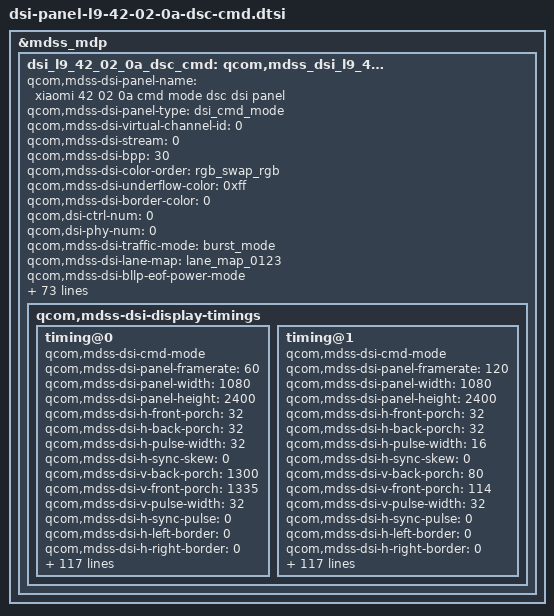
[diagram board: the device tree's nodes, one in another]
&mdss_mdp {
	dsi_l9_42_02_0a_dsc_cmd: qcom,mdss_dsi_l9_42_02_0a_dsc_cmd {
		qcom,mdss-dsi-panel-name = "xiaomi 42 02 0a cmd mode dsc dsi panel";
		qcom,mdss-dsi-panel-type = "dsi_cmd_mode";
		qcom,mdss-dsi-virtual-channel-id = <0>;
		qcom,mdss-dsi-stream = <0>;
		qcom,mdss-dsi-bpp = <30>;
		qcom,mdss-dsi-color-order = "rgb_swap_rgb";
		qcom,mdss-dsi-underflow-color = <0xff>;
		qcom,mdss-dsi-border-color = <0>;

		qcom,dsi-ctrl-num = <0>;
		qcom,dsi-phy-num = <0>;

		qcom,mdss-dsi-traffic-mode = "burst_mode";
		qcom,mdss-dsi-lane-map = "lane_map_0123";
		qcom,mdss-dsi-bllp-eof-power-mode;
		qcom,mdss-dsi-bllp-power-mode;
		qcom,mdss-dsi-lane-0-state;
		qcom,mdss-dsi-lane-1-state;
		qcom,mdss-dsi-lane-2-state;
		qcom,mdss-dsi-lane-3-state;
		qcom,mdss-dsi-dma-trigger = "trigger_sw";
		qcom,mdss-dsi-mdp-trigger = "none";
		qcom,mdss-dsi-reset-sequence =  <1 11>, <0 1>, <1 11>;
		qcom,mdss-pan-physical-width-dimension = <683>;
		qcom,mdss-pan-physical-height-dimension = <1517>;
		qcom,mdss-dsi-te-pin-select = <1>;
		qcom,mdss-dsi-wr-mem-start = <0x2c>;
		qcom,mdss-dsi-wr-mem-continue = <0x3c>;
		qcom,mdss-dsi-te-dcs-command = <1>;
		qcom,mdss-dsi-te-check-enable;
		qcom,mdss-dsi-te-using-te-pin;
		qcom,mdss-dsi-tx-eot-append;
		qcom,mdss-dsi-lp11-init;

		qcom,mdss-dsi-bl-inverted-dbv;
		qcom,bl-update-flag = "delay_until_first_frame";
		qcom,mdss-dsi-panel-mode-switch;

		qcom,mdss-dsi-panel-hdr-enabled;
		qcom,mdss-dsi-panel-hdr-color-primaries = <14500 15500 32000 17000 15500 30000 8000 3000>;
		qcom,mdss-dsi-panel-peak-brightness = <4200000>;
		qcom,mdss-dsi-panel-blackness-level = <3230>;

		qcom,mdss-dsi-display-timings {
			timing@0{
				qcom,mdss-dsi-cmd-mode;
				qcom,mdss-dsi-panel-framerate = <60>;
				qcom,mdss-dsi-panel-width = <1080>;
				qcom,mdss-dsi-panel-height = <2400>;
				qcom,mdss-dsi-h-front-porch = <32>;
				qcom,mdss-dsi-h-back-porch = <32>;
				qcom,mdss-dsi-h-pulse-width = <32>;
				qcom,mdss-dsi-h-sync-skew = <0>;
				qcom,mdss-dsi-v-back-porch = <1300>;
				qcom,mdss-dsi-v-front-porch = <1335>;
				qcom,mdss-dsi-v-pulse-width = <32>;
				qcom,mdss-dsi-h-sync-pulse = <0>;
				qcom,mdss-dsi-h-left-border = <0>;
				qcom,mdss-dsi-h-right-border = <0>;
				qcom,mdss-dsi-v-top-border = <0>;
				qcom,mdss-dsi-v-bottom-border = <0>;
				qcom,mdss-dsi-panel-clockrate = <831000000>;
				qcom,mdss-dsi-panel-jitter = <0x5 0x1>;
				qcom,mdss-mdp-transfer-time-us = <7000>;
				qcom,mdss-dsi-on-command = [
					/* VDC setting */
					39 01 00 00 00 00 06 F0 55 AA 52 08 08
					39 00 00 00 00 00 05 E9 00 00 00 16
					39 00 00 00 00 00 02 6F 07
					39 00 00 00 00 00 05 B9 05 DB 00 7A
					/* RCN setting */
					39 00 00 00 00 00 05 FF AA 55 A5 80
					39 00 00 00 00 00 02 6F 1D
					39 00 00 00 00 00 02 F2 05
					/* Page 0 */
					39 00 00 00 00 00 06 F0 55 AA 52 08 00
					39 00 00 00 00 00 02 6F 01
					39 00 00 00 00 00 02 CA AA
					/* flash reload */
					39 00 00 00 00 00 02 6F 01
					39 00 00 00 00 00 02 C0 B3
					39 00 00 00 00 00 02 6F 11
					39 00 00 00 00 00 02 C0 30
					39 00 00 00 00 00 02 6F 1C
					/* Demura gain */
					39 00 00 00 00 00 03 C0 03 12
					/* VBP & VFP */
					39 00 00 00 00 00 05 3B 00 14 00 12
					/* DSC Setting */
					39 00 00 00 00 00 02 90 01
					39 00 00 00 00 00 13 91 AB 28 00 0C C2 00 03 1C 01 7E 00 0F 08 BB 04 3D 10 F0
					39 00 00 00 00 00 02 03 01
					39 00 00 00 00 00 02 2C 00
					/* Round Off */
					39 00 00 00 00 00 06 F0 55 AA 52 08 07
					39 00 00 00 00 00 02 C0 01
					39 00 00 00 00 00 02 C1 00
					39 00 00 00 00 00 02 C2 00
					39 00 00 00 00 00 02 C3 00
					39 00 00 00 00 00 02 C4 00
					39 00 00 00 00 00 02 C5 00
					39 00 00 00 00 00 02 C6 00
					39 00 00 00 00 00 02 C7 00
					39 00 00 00 00 00 02 C8 00
					39 00 00 00 00 00 02 CD 00
					39 00 00 00 00 00 02 CE 00
					39 00 00 00 00 00 02 CF 00
					39 00 00 00 00 00 02 D0 00
					/* Dimming OFF Setting */
					39 00 00 00 00 00 02 53 20
					/* page 0 */
					39 00 00 00 00 00 06 F0 55 AA 52 08 00
					/* Dimming 8 frame */
					39 00 00 00 00 00 02 6F 02
					39 00 00 00 00 00 03 B2 08 08
					/* TE ON Setting */
					39 00 00 00 00 00 02 35 00
					/* CASET/RASET Setting */
					39 00 00 00 00 00 05 2A 00 00 04 37 /* CASET 1080 */
					39 00 00 00 00 00 05 2B 00 00 09 5F /* PASET 2400 */
					/* MIPI Speed = 831Mbps @osc 128Mhz */
					/* page 1 */
					39 00 00 00 00 00 06 F0 55 AA 52 08 01
					39 00 00 00 00 00 08 C3 94 01 8C D0 22 02 00
					/* Frame Rate 60Hz */
					39 00 00 00 00 00 02 2F 02
					/* GIR OFF */
					39 00 00 00 00 00 02 5F 01
					/* Page 0 */
					39 00 00 00 00 00 06 F0 55 AA 52 08 00
					39 00 00 00 00 00 02 6F 09
					/* Normal gamma */
					39 00 00 00 00 00 02 C0 00
					/* Page 2 */
					39 00 00 00 00 00 06 F0 55 AA 52 08 02
					39 00 00 00 00 00 02 CC 30
					39 01 00 00 14 00 02 CE 01
					39 00 00 00 00 00 02 CC 00
					/* cmd3: aod no black */
					39 00 00 00 00 00 05 FF AA 55 A5 80
					39 00 00 00 00 00 02 6F 61
					39 00 00 00 00 00 02 F3 80
					39 00 00 00 00 00 06 F0 55 AA 52 08 01
					39 00 00 00 00 00 02 6F 01
					39 00 00 00 00 00 04 D2 00 00 11
					39 00 00 00 00 00 02 6F 06
					39 00 00 00 00 00 02 D2 05
					39 00 00 00 00 00 02 6F 0F
					39 00 00 00 00 00 02 D2 00
					39 00 00 00 00 00 02 6F 09
					39 00 00 00 00 00 03 D2 00 00
					/* Close ELVSS and ELVDD PMIC-Fast Discharge*/
					39 00 00 00 00 00 06 F0 55 AA 52 08 01
					39 01 00 00 00 00 02 CE 08
					/* Sleep Out */
					39 01 00 00 78 00 02 11 00
					/* Display On */
					39 01 00 00 00 00 02 29 00
					/* Close ELVSS and ELVDD PMIC-Fast Discharge*/
					39 00 00 00 00 00 06 F0 55 AA 52 08 01
					39 01 00 00 00 00 02 CE 00];
				qcom,mdss-dsi-off-command = [
					39 01 00 00 0A 00 02 28 00
					39 01 00 00 78 00 02 10 00];
				qcom,mdss-dsi-on-command-state = "dsi_lp_mode";
				qcom,mdss-dsi-off-command-state = "dsi_lp_mode";

				qcom,mdss-dsi-timing-switch-command = [
					/* Frame Rate 60Hz GIR off*/
					/* page 0 */
					39 01 00 00 00 00 06 F0 55 AA 52 08 00
					/* 60Hz */
					39 00 00 00 00 00 02 2F 02
					/* GIR OFF */
					39 00 00 00 00 00 02 5F 01
					39 00 00 00 00 00 06 F0 55 AA 52 08 00
					39 00 00 00 00 00 02 6F 09
					/* Normal gamma */
					39 00 00 00 00 00 02 C0 00
					/* Page 2 */
					39 00 00 00 00 00 06 F0 55 AA 52 08 02
					39 00 00 00 00 00 02 CC 30
					39 01 00 00 14 00 02 CE 01
					39 01 00 00 00 00 02 CC 00
				];
				qcom,mdss-dsi-timing-switch-command-state = "dsi_hs_mode";

				qcom,mdss-dsi-lp1-command = [
					39 01 00 00 14 00 02 39 00
					39 01 00 00 00 00 02 2C 00];
				qcom,mdss-dsi-lp1-commandd-state = "dsi_hs_mode";

				qcom,mdss-dsi-nolp-command = [
					39 01 00 00 32 00 02 38 00
					39 01 00 00 00 00 02 2C 00];
				qcom,mdss-dsi-nolp-command-state = "dsi_hs_mode";

				qcom,compression-mode = "dsc";
				qcom,mdss-dsc-version = <0x11>;
				qcom,mdss-dsc-scr-version = <0x0>;
				qcom,mdss-dsc-slice-height = <12>;
				qcom,mdss-dsc-slice-width = <1080>;
				qcom,mdss-dsc-slice-per-pkt = <1>;
				qcom,mdss-dsc-bit-per-component = <10>;
				qcom,mdss-dsc-bit-per-pixel = <8>;
				qcom,mdss-dsc-block-prediction-enable;
			};
			timing@1{
				qcom,mdss-dsi-cmd-mode;
				qcom,mdss-dsi-panel-framerate = <120>;
				qcom,mdss-dsi-panel-width = <1080>;
				qcom,mdss-dsi-panel-height = <2400>;
				qcom,mdss-dsi-h-front-porch = <32>;
				qcom,mdss-dsi-h-back-porch = <32>;
				qcom,mdss-dsi-h-pulse-width = <16>;
				qcom,mdss-dsi-h-sync-skew = <0>;
				qcom,mdss-dsi-v-back-porch = <80>;
				qcom,mdss-dsi-v-front-porch = <114>;
				qcom,mdss-dsi-v-pulse-width = <32>;
				qcom,mdss-dsi-h-sync-pulse = <0>;
				qcom,mdss-dsi-h-left-border = <0>;
				qcom,mdss-dsi-h-right-border = <0>;
				qcom,mdss-dsi-v-top-border = <0>;
				qcom,mdss-dsi-v-bottom-border = <0>;
				qcom,mdss-dsi-panel-clockrate = <831000000>;
				qcom,mdss-dsi-panel-jitter = <0x5 0x1>;
				qcom,mdss-mdp-transfer-time-us = <7000>;
				qcom,mdss-dsi-on-command = [
					/* VDC setting */
					39 01 00 00 00 00 06 F0 55 AA 52 08 08
					39 00 00 00 00 00 05 E9 00 00 00 16
					39 00 00 00 00 00 02 6F 07
					39 00 00 00 00 00 05 B9 05 DB 00 7A
					/* RCN setting */
					39 00 00 00 00 00 05 FF AA 55 A5 80
					39 00 00 00 00 00 02 6F 1D
					39 00 00 00 00 00 02 F2 05
					/* Page 0 */
					39 00 00 00 00 00 06 F0 55 AA 52 08 00
					39 00 00 00 00 00 02 6F 01
					39 00 00 00 00 00 02 CA AA
					/* flash reload */
					39 00 00 00 00 00 02 6F 01
					39 00 00 00 00 00 02 C0 B3
					39 00 00 00 00 00 02 6F 11
					39 00 00 00 00 00 02 C0 30
					39 00 00 00 00 00 02 6F 1C
					/* Demura gain */
					39 00 00 00 00 00 03 C0 03 12
					/* VBP & VFP */
					39 00 00 00 00 00 05 3B 00 14 00 12
					/* DSC Setting */
					39 00 00 00 00 00 02 90 01
					39 00 00 00 00 00 13 91 AB 28 00 0C C2 00 03 1C 01 7E 00 0F 08 BB 04 3D 10 F0
					39 00 00 00 00 00 02 03 01
					39 00 00 00 00 00 02 2C 00
					/* Round Off */
					39 00 00 00 00 00 06 F0 55 AA 52 08 07
					39 00 00 00 00 00 02 C0 01
					39 00 00 00 00 00 02 C1 00
					39 00 00 00 00 00 02 C2 00
					39 00 00 00 00 00 02 C3 00
					39 00 00 00 00 00 02 C4 00
					39 00 00 00 00 00 02 C5 00
					39 00 00 00 00 00 02 C6 00
					39 00 00 00 00 00 02 C7 00
					39 00 00 00 00 00 02 C8 00
					39 00 00 00 00 00 02 CD 00
					39 00 00 00 00 00 02 CE 00
					39 00 00 00 00 00 02 CF 00
					39 00 00 00 00 00 02 D0 00
					/* Dimming OFF Setting */
					39 00 00 00 00 00 02 53 20
					/* page 0 */
					39 00 00 00 00 00 06 F0 55 AA 52 08 00
					/* Dimming 8 frame */
					39 00 00 00 00 00 02 6F 02
					39 00 00 00 00 00 03 B2 08 08
					/* TE ON Setting */
					39 00 00 00 00 00 02 35 00
					/* CASET/RASET Setting */
					39 00 00 00 00 00 05 2A 00 00 04 37 /* CASET 1080 */
					39 00 00 00 00 00 05 2B 00 00 09 5F /* PASET 2400 */
					/* MIPI Speed = 831Mbps @osc 128Mhz */
					/* page 1 */
					39 00 00 00 00 00 06 F0 55 AA 52 08 01
					39 00 00 00 00 00 08 C3 94 01 8C D0 22 02 00
					/* Frame Rate 120Hz */
					39 00 00 00 00 00 02 2F 03
					/* GIR OFF */
					39 00 00 00 00 00 02 5F 01
					/* Page 0 */
					39 00 00 00 00 00 06 F0 55 AA 52 08 00
					39 00 00 00 00 00 02 6F 0A
					/* Preset1 gamma */
					39 00 00 00 00 00 02 C0 20
					/* Page 2 */
					39 00 00 00 00 00 06 F0 55
					 AA 52 08 02
					39 00 00 00 00 00 02 CC 30
					39 01 00 00 14 00 02 CE 01
					39 00 00 00 00 00 02 CC 00
					/* cmd3: aod no black */
					39 00 00 00 00 00 05 FF AA 55 A5 80
					39 00 00 00 00 00 02 6F 61
					39 00 00 00 00 00 02 F3 80
					39 00 00 00 00 00 06 F0 55 AA 52 08 01
					39 00 00 00 00 00 02 6F 01
					39 00 00 00 00 00 04 D2 00 00 11
					39 00 00 00 00 00 02 6F 06
					39 00 00 00 00 00 02 D2 05
					39 00 00 00 00 00 02 6F 0F
					39 00 00 00 00 00 02 D2 00
					39 00 00 00 00 00 02 6F 09
					39 00 00 00 00 00 03 D2 00 00
					/* Close ELVSS and ELVDD PMIC-Fast Discharge*/
					39 00 00 00 00 00 06 F0 55 AA 52 08 01
					39 01 00 00 00 00 02 CE 08
					/* Sleep Out */
					39 01 00 00 78 00 02 11 00
					/* Display On */
					39 01 00 00 00 00 02 29 00
					/* Close ELVSS and ELVDD PMIC-Fast Discharge*/
					39 00 00 00 00 00 06 F0 55 AA 52 08 01
					39 01 00 00 00 00 02 CE 00];
				qcom,mdss-dsi-off-command = [
					39 01 00 00 14 00 02 28 00
					39 01 00 00 78 00 02 10 00];
				qcom,mdss-dsi-on-command-state = "dsi_lp_mode";
				qcom,mdss-dsi-off-command-state = "dsi_lp_mode";

				qcom,mdss-dsi-timing-switch-command = [
					/* Frame Rate 120Hz GIR off*/
					/* Page 0 */
					39 01 00 00 00 00 06 F0 55 AA 52 08 00
					/* 120Hz */
					39 00 00 00 00 00 02 2F 03
					/* GIR OFF */
					39 00 00 00 00 00 02 5F 01
					39 00 00 00 00 00 06 F0 55 AA 52 08 00
					39 00 00 00 00 00 02 6F 0A
					/* Preset1 gamma */
					39 00 00 00 00 00 02 C0 20
					/* Page 2 */
					39 00 00 00 00 00 06 F0 55 AA 52 08 02
					39 00 00 00 00 00 02 CC 30
					39 01 00 00 14 00 02 CE 01
					39 01 00 00 00 00 02 CC 00

				];
				qcom,mdss-dsi-timing-switch-command-state = "dsi_hs_mode";

				qcom,mdss-dsi-lp1-command = [
					39 01 00 00 14 00 02 39 00
					39 01 00 00 00 00 02 2C 00];
				qcom,mdss-dsi-lp1-commandd-state = "dsi_hs_mode";

				qcom,mdss-dsi-nolp-command = [
					39 01 00 00 32 00 02 38 00
					39 01 00 00 00 00 02 2C 00];
				qcom,mdss-dsi-nolp-command-state = "dsi_hs_mode";

				qcom,compression-mode = "dsc";
				qcom,mdss-dsc-version = <0x11>;
				qcom,mdss-dsc-scr-version = <0x0>;
				qcom,mdss-dsc-slice-height = <12>;
				qcom,mdss-dsc-slice-width = <1080>;
				qcom,mdss-dsc-slice-per-pkt = <1>;
				qcom,mdss-dsc-bit-per-component = <10>;
				qcom,mdss-dsc-bit-per-pixel = <8>;
				qcom,mdss-dsc-block-prediction-enable;
			};
		};
	};
};

&dsi_l9_42_02_0a_dsc_cmd {
	mi,panel-id = <0x00004C39 0x00420200>;
	mi,hbm-51-ctl-flag;
	mi,bl-51ctl-32bit-flag;
	mi,aod-bl-51ctl-flag;
	mi,aod-brightness = <0x155 0x0FFE>;
	mi,hbm-off-51-index = <0>;
	mi,hbm-fod-off-51-index = <0>;
	mi,hbm-bl-min-level = <1>;
	mi,hbm-bl-max-level = <2047>;
	mi,max-brightness-clone = <4095>;
	mi,thermal-dimming-flag;
	mi,mdss-dsi-panel-dc-type = <0>;

	mi,panel-hbm-backlight-threshold = <2047>;

	mi,local-hbm-enabled;
	mi,local-hbm-off-to-hbm-51-index = <1>;
	mi,local-hbm-off-to-normal-51-index = <1>;
	mi,local-hbm-normal-alpha-87-index = <13>;
	mi,local-hbm-hlpm-alpha-87-index = <16>;
	mi,local-hbm-on-87-index = <11>;
	mi,local-hbm-hlpm-on-87-index = <14>;
	mi,doze-hbm-dbv-level = <245>;
	mi,doze-lbm-dbv-level = <20>;
	mi,fod-low-brightness-clone-threshold = <38>;
	mi,fod-low-brightness-lux-threshold = <1>;

	mi,flatmode-update-flag;
	mi,flatmode-on-b9-index = <3>;
	mi,update-vdc-param-enabled;
	mi,dsi-on-e9-index = <1>;
	mi,dsi-on-b9-index = <3>;

	mi,lhbm-update-flag;

	/* IRQF_ONESHOT | IRQF_TRIGGER_FALLING */
	mi,esd-err-irq-gpio = <&tlmm 3 0x2002>;

	mi,panel-aod-to-off-command-need-enabled;

	mi,panel-on-dimming-delay = <120>;

	qcom,esd-check-enabled;
	qcom,esd-aod-check-enabled;
	qcom,mdss-dsi-panel-status-check-mode = "reg_read";
	qcom,mdss-dsi-panel-status-offset-command = [
		39 01 00 00 00 00 05 FF AA 55 A5 81
		15 01 00 00 00 00 02 6F 0F];
	qcom,mdss-dsi-panel-status-command = [06 01 00 00 00 00 01 FA];
	qcom,mdss-dsi-panel-status-command-state = "dsi_lp_mode";
	qcom,mdss-dsi-panel-status-offset-command-state = "dsi_lp_mode";
	qcom,mdss-dsi-panel-status-value = <0x00>;
	qcom,mdss-dsi-panel-status-read-length = <1>;

	qcom,mdss-dsi-display-timings {
		timing@0{ /* 60hz */
			mi,mdss-dsc-panel-id = <0x00004C39 0x00420200>;
			mi,mdss-dsi-dimmingon-command = [15 01 00 00 00 00 02 53 28];
			mi,mdss-dsi-dimmingon-command-state = "dsi_hs_mode";
			mi,mdss-dsi-dimmingoff-command = [15 01 00 00 00 00 02 53 20];
			mi,mdss-dsi-dimmingoff-command-state = "dsi_hs_mode";

			mi,mdss-dsi-hbm-on-command = [39 01 00 00 00 00 03 51 0F FF];
			mi,mdss-dsi-hbm-on-command-state = "dsi_hs_mode";
			mi,mdss-dsi-hbm-off-command = [39 01 00 00 00 00 03 51 07 FF];
			mi,mdss-dsi-hbm-off-command-state = "dsi_hs_mode";

			mi,mdss-dsi-doze-hbm-command = [
				39 01 00 00 00 00 05 51 00 F5 0F FE
				39 01 00 00 14 00 02 39 00
				39 01 00 00 00 00 02 2C 00
			];
			mi,mdss-dsi-doze-hbm-command-state = "dsi_hs_mode";
			mi,mdss-dsi-doze-lbm-command = [
				39 01 00 00 00 00 05 51 00 14 01 55
				39 01 00 00 32 00 02 39 00
				39 01 00 00 00 00 02 2C 00
			];
			mi,mdss-dsi-doze-lbm-command-state = "dsi_hs_mode";

			mi,mdss-dsi-doze-hbm-nolp-command = [
				/* AOD off */
				39 01 00 00 32 00 02 38 00
				39 00 00 00 00 00 02 2C 00
				39 01 00 00 00 00 05 51 00 F5 0F FE
			];
			mi,mdss-dsi-doze-hbm-nolp-command-state = "dsi_hs_mode";
			mi,mdss-dsi-doze-lbm-nolp-command = [
				/* AOD off */
				39 01 00 00 32 00 02 38 00
				39 00 00 00 00 00 02 2C 00
				39 01 00 00 00 00 05 51 00 14 01 55
			];
			mi,mdss-dsi-doze-lbm-nolp-command-state = "dsi_hs_mode";

			mi,mdss-dsi-doze-none-nolp-command = [
				/* AOD off */
				39 01 00 00 32 00 02 38 00
				39 01 00 00 00 00 02 2C 00
			];
			mi,mdss-dsi-doze-none-nolp-command-state = "dsi_hs_mode";

			mi,mdss-dsi-local-hbm-normal-white-1000nit-command = [
				39 01 00 00 00 00 06 F0 55 AA 52 08 00
				39 00 00 00 00 00 02 6F 17
				39 00 00 00 00 00 03 B2 07 FF
				39 00 00 00 00 00 02 6F 1F
				39 00 00 00 00 00 03 B2 00 50
				39 00 00 00 00 00 06 F0 55 AA 52 08 02
				39 00 00 00 00 00 02 D1 01
				39 00 00 00 00 00 02 6F 08
				39 00 00 00 00 00 07 D0 0B 07 09 7B 0C 1D
				39 00 00 00 00 00 06 F0 55 AA 52 08 07
				39 00 00 00 00 00 02 D9 40
				39 00 00 00 00 00 02 6F 01
				39 00 00 00 00 00 05 88 02 1C 08 65
				39 00 00 00 00 00 03 87 1F FF
				39 00 00 00 00 00 03 51 07 FF
				39 00 00 00 00 00 02 88 01
				39 01 00 00 42 00 02 85 01
			];
			mi,mdss-dsi-local-hbm-normal-white-1000nit-command-state = "dsi_hs_mode";

			mi,mdss-dsi-local-hbm-hlpm-white-1000nit-command = [
				/* AOD off */
				39 01 00 00 32 00 02 38 00
				39 00 00 00 00 00 02 2C 00
				/* 60HZ */
				39 00 00 00 00 00 02 2F 02
				/* Local HBM setting*/
				39 00 00 00 00 00 06 F0 55 AA 52 08 00
				39 00 00 00 00 00 02 6F 17
				39 00 00 00 00 00 03 B2 07 FF
				39 00 00 00 00 00 02 6F 1F
				39 00 00 00 00 00 03 B2 00 50
				39 00 00 00 00 00 06 F0 55 AA 52 08 02
				39 00 00 00 00 00 02 D1 01
				39 00 00 00 00 00 02 6F 08
				39 00 00 00 00 00 07 D0 0B 07 09 7B 0C 1D
				39 00 00 00 00 00 06 F0 55 AA 52 08 07
				39 00 00 00 00 00 02 D9 40
				39 00 00 00 00 00 02 6F 01
				39 00 00 00 00 00 05 88 02 1C 08 65
				39 00 00 00 00 00 03 87 1F FF
				39 00 00 00 00 00 03 51 07 FF
				39 00 00 00 00 00 02 88 01
				39 01 00 00 42 00 02 85 01
			];
			mi,mdss-dsi-local-hbm-hlpm-white-1000nit-command-state = "dsi_hs_mode";

			mi,mdss-dsi-local-hbm-normal-white-110nit-command = [
				39 01 00 00 00 00 06 F0 55 AA 52 08 00
				39 00 00 00 00 00 02 6F 17
				39 00 00 00 00 00 03 B2 07 FF
				39 00 00 00 00 00 02 6F 1F
				39 00 00 00 00 00 03 B2 00 50
				39 00 00 00 00 00 06 F0 55 AA 52 08 02
				39 00 00 00 00 00 02 D1 01
				39 00 00 00 00 00 02 6F 08
				39 00 00 00 00 00 07 D0 07 62 06 74 07 F7
				39 00 00 00 00 00 06 F0 55 AA 52 08 07
				39 00 00 00 00 00 02 D9 40
				39 00 00 00 00 00 02 6F 01
				39 00 00 00 00 00 05 88 02 1C 08 65
				39 00 00 00 00 00 03 87 1F FF
				39 00 00 00 00 00 03 51 07 FF
				39 00 00 00 00 00 02 88 01
				39 01 00 00 42 00 02 85 01
			];
			mi,mdss-dsi-local-hbm-normal-white-110nit-command-state = "dsi_hs_mode";

			mi,mdss-dsi-local-hbm-hlpm-white-110nit-command = [
				/* AOD off */
				39 01 00 00 32 00 02 38 00
				39 00 00 00 00 00 02 2C 00
				/* 60HZ */
				39 00 00 00 00 00 02 2F 02
				/* Local HBM setting*/
				39 00 00 00 00 00 06 F0 55 AA 52 08 00
				39 00 00 00 00 00 02 6F 17
				39 00 00 00 00 00 03 B2 07 FF
				39 00 00 00 00 00 02 6F 1F
				39 00 00 00 00 00 03 B2 00 50
				39 00 00 00 00 00 06 F0 55 AA 52 08 02
				39 00 00 00 00 00 02 D1 01
				39 00 00 00 00 00 02 6F 08
				39 00 00 00 00 00 07 D0 07 62 06 74 07 F7
				39 00 00 00 00 00 06 F0 55 AA 52 08 07
				39 00 00 00 00 00 02 D9 40
				39 00 00 00 00 00 02 6F 01
				39 00 00 00 00 00 05 88 02 1C 08 65
				39 00 00 00 00 00 03 87 1F FF
				39 00 00 00 00 00 03 51 07 FF
				39 00 00 00 00 00 02 88 01
				39 01 00 00 42 00 02 85 01
			];
			mi,mdss-dsi-local-hbm-hlpm-white-110nit-command-state = "dsi_hs_mode";

			mi,mdss-dsi-local-hbm-normal-green-500nit-command = [
				39 01 00 00 00 00 06 F0 55 AA 52 08 00
				39 00 00 00 00 00 02 6F 17
				39 00 00 00 00 00 03 B2 07 FF
				39 00 00 00 00 00 02 6F 1F
				39 00 00 00 00 00 03 B2 00 50
				39 00 00 00 00 00 06 F0 55 AA 52 08 02
				39 00 00 00 00 00 02 D1 01
				39 00 00 00 00 00 02 6F 08
				39 00 00 00 00 00 07 D0 00 00 09 40 00 00
				39 00 00 00 00 00 06 F0 55 AA 52 08 07
				39 00 00 00 00 00 02 D9 40
				39 00 00 00 00 00 02 6F 01
				39 00 00 00 00 00 05 88 02 1C 08 65
				39 00 00 00 00 00 03 87 1F FF
				39 00 00 00 00 00 03 51 07 FF
				39 00 00 00 00 00 02 88 01
				39 01 00 00 42 00 02 85 01
			];
			mi,mdss-dsi-local-hbm-normal-green-500nit-command-state = "dsi_hs_mode";

			mi,mdss-dsi-local-hbm-off-to-normal-command = [
				39 01 00 00 00 00 02 53 20
				39 00 00 00 00 00 03 51 00 00
				39 00 00 00 00 00 03 87 0F FF
				39 00 00 00 00 00 02 88 01
				39 01 00 00 0A 00 02 86 01
			];
			mi,mdss-dsi-local-hbm-off-to-normal-command-state = "dsi_hs_mode";

			mi,mdss-dsi-local-hbm-off-to-hbm-command = [
				39 01 00 00 00 00 02 53 20
				39 00 00 00 00 00 03 51 00 00
				39 00 00 00 00 00 03 87 0F FF
				39 00 00 00 00 00 02 88 01
				39 01 00 00 0A 00 02 86 01
			];
			mi,mdss-dsi-local-hbm-off-to-hbm-command-state = "dsi_hs_mode";

			mi,mdss-dsi-local-hbm-off-to-hlpm-command = [
				/* local hbm off */
				39 01 00 00 00 00 02 53 20
				39 00 00 00 00 00 03 51 00 00
				39 00 00 00 00 00 03 87 0F FF
				39 00 00 00 00 00 02 88 01
				39 01 00 00 0A 00 02 86 01
				/* aod hbm */
				39 01 00 00 14 00 02 39 00
				39 01 00 00 00 00 02 2C 00
			];
			mi,mdss-dsi-local-hbm-off-to-hlpm-command-state = "dsi_hs_mode";

			mi,mdss-dsi-local-hbm-off-to-llpm-command = [
				/* local hbm off */
				39 01 00 00 00 00 02 53 20
				39 00 00 00 00 00 03 51 00 00
				39 00 00 00 00 00 03 87 0F FF
				39 00 00 00 00 00 02 88 01
				39 01 00 00 0A 00 02 86 01
				/* aod lbm */
				39 01 00 00 14 00 02 39 00
				39 01 00 00 00 00 02 2C 00
			];
			mi,mdss-dsi-local-hbm-off-to-llpm-command-state = "dsi_hs_mode";

			mi,mdss-dsi-flat-mode-on-command = [
				/* page 0 */
				39 01 00 00 00 00 06 F0 55 AA 52 08 00
				/* 60Hz */
				39 00 00 00 00 00 02 2F 02
				/* GIR ON */
				39 00 00 00 00 00 02 5F 00
				39 00 00 00 00 00 06 F0 55 AA 52 08 00
				39 00 00 00 00 00 02 6F 09
				/* Preset2 gamma */
				39 00 00 00 00 00 02 C0 40
				/* page 2 */
				39 00 00 00 00 00 06 F0 55 AA 52 08 02
				39 00 00 00 00 00 02 CC 30
				39 01 00 00 14 00 02 CE 01
				39 01 00 00 00 00 02 CC 00
			];
			mi,mdss-dsi-flat-mode-on-command-state = "dsi_hs_mode";

			mi,mdss-dsi-flat-mode-off-command = [
				/* page 0 */
				39 01 00 00 00 00 06 F0 55 AA 52 08 00
				/* 60Hz */
				39 00 00 00 00 00 02 2F 02
				/* GIR OFF */
				39 00 00 00 00 00 02 5F 01
				39 00 00 00 00 00 06 F0 55 AA 52 08 00
				39 00 00 00 00 00 02 6F 09
				/* Normal gamma */
				39 00 00 00 00 00 02 C0 00
				/* Page 2 */
				39 00 00 00 00 00 06 F0 55 AA 52 08 02
				39 00 00 00 00 00 02 CC 30
				39 01 00 00 14 00 02 CE 01
				39 01 00 00 00 00 02 CC 00
			];
			mi,mdss-dsi-flat-mode-off-command-state = "dsi_hs_mode";

			mi,mdss-dsi-timing-switch-gir-command = [
				/* Frame Rate 60Hz GIR ON */
				/* page 0 */
				39 01 00 00 00 00 06 F0 55 AA 52 08 00
				/* 60Hz */
				39 00 00 00 00 00 02 2F 02
				/* GIR ON */
				39 00 00 00 00 00 02 5F 00
				39 00 00 00 00 00 06 F0 55 AA 52 08 00
				39 00 00 00 00 00 02 6F 09
				/* Preset2 gamma */
				39 00 00 00 00 00 02 C0 40
				/* page 2 */
				39 00 00 00 00 00 06 F0 55 AA 52 08 02
				39 00 00 00 00 00 02 CC 30
				39 01 00 00 14 00 02 CE 01
				39 01 00 00 00 00 02 CC 00
			];
			mi,mdss-dsi-timing-switch-gir-command-state = "dsi_hs_mode";

			mi,mdss-dsi-pre-doze-to-off-command = [
				39 01 00 00 00 00 06 F0 55 AA 52 08 01
				39 01 00 00 00 00 02 CE 0C];
			mi,mdss-dsi-pre-doze-to-off-command-state = "dsi_hs_mode";
		};
		timing@1{ /* 120hz */
			mi,mdss-dsc-panel-id = <0x00004C39 0x00420200>;
			mi,mdss-dsi-dimmingon-command = [15 01 00 00 00 00 02 53 28];
			mi,mdss-dsi-dimmingon-command-state = "dsi_hs_mode";
			mi,mdss-dsi-dimmingoff-command = [15 01 00 00 00 00 02 53 20];
			mi,mdss-dsi-dimmingoff-command-state = "dsi_hs_mode";

			mi,mdss-dsi-hbm-on-command = [39 01 00 00 00 00 03 51 0F FF];
			mi,mdss-dsi-hbm-on-command-state = "dsi_hs_mode";
			mi,mdss-dsi-hbm-off-command = [39 01 00 00 00 00 03 51 07 FF];
			mi,mdss-dsi-hbm-off-command-state = "dsi_hs_mode";

			mi,mdss-dsi-doze-hbm-command = [
				39 01 00 00 00 00 05 51 00 F5 0F FE
				39 01 00 00 14 00 02 39 00
				39 01 00 00 00 00 02 2C 00
			];
			mi,mdss-dsi-doze-hbm-command-state = "dsi_hs_mode";
			mi,mdss-dsi-doze-lbm-command = [
				39 01 00 00 00 00 05 51 00 14 01 55
				39 01 00 00 32 00 02 39 00
				39 01 00 00 00 00 02 2C 00
			];
			mi,mdss-dsi-doze-lbm-command-state = "dsi_hs_mode";

			mi,mdss-dsi-doze-hbm-nolp-command = [
				/* AOD off */
				39 01 00 00 32 00 02 38 00
				39 00 00 00 00 00 02 2C 00
				39 01 00 00 00 00 05 51 00 F5 0F FE
			];
			mi,mdss-dsi-doze-hbm-nolp-command-state = "dsi_hs_mode";
			mi,mdss-dsi-doze-lbm-nolp-command = [
				/* AOD off */
				39 01 00 00 32 00 02 38 00
				39 00 00 00 00 00 02 2C 00
				39 01 00 00 00 00 05 51 00 14 01 55
			];
			mi,mdss-dsi-doze-lbm-nolp-command-state = "dsi_hs_mode";

			mi,mdss-dsi-doze-none-nolp-command = [
				/* AOD off */
				39 01 00 00 32 00 02 38 00
				39 01 00 00 00 00 02 2C 00
			];
			mi,mdss-dsi-doze-none-nolp-command-state = "dsi_hs_mode";

			mi,mdss-dsi-local-hbm-normal-white-1000nit-command = [
				39 01 00 00 00 00 06 F0 55 AA 52 08 00
				39 00 00 00 00 00 02 6F 17
				39 00 00 00 00 00 03 B2 07 FF
				39 00 00 00 00 00 02 6F 1F
				39 00 00 00 00 00 03 B2 00 50
				39 00 00 00 00 00 06 F0 55 AA 52 08 02
				39 00 00 00 00 00 02 D1 01
				39 00 00 00 00 00 02 6F 08
				39 00 00 00 00 00 07 D0 0B 07 09 7B 0C 1D
				39 00 00 00 00 00 06 F0 55 AA 52 08 07
				39 00 00 00 00 00 02 D9 40
				39 00 00 00 00 00 02 6F 01
				39 00 00 00 00 00 05 88 02 1C 08 65
				39 00 00 00 00 00 03 87 1F FF
				39 00 00 00 00 00 03 51 07 FF
				39 00 00 00 00 00 02 88 01
				39 01 00 00 21 00 02 85 01
			];
			mi,mdss-dsi-local-hbm-normal-white-1000nit-command-state = "dsi_hs_mode";

			mi,mdss-dsi-local-hbm-hlpm-white-1000nit-command = [
				/* AOD off */
				39 01 00 00 32 00 02 38 00
				39 00 00 00 00 00 02 2C 00
				/* 120HZ */
				39 00 00 00 00 00 02 2F 03
				/* Local HBM setting*/
				39 00 00 00 00 00 06 F0 55 AA 52 08 00
				39 00 00 00 00 00 02 6F 17
				39 00 00 00 00 00 03 B2 07 FF
				39 00 00 00 00 00 02 6F 1F
				39 00 00 00 00 00 03 B2 00 50
				39 00 00 00 00 00 06 F0 55 AA 52 08 02
				39 00 00 00 00 00 02 D1 01
				39 00 00 00 00 00 02 6F 08
				39 00 00 00 00 00 07 D0 0B 07 09 7B 0C 1D
				39 00 00 00 00 00 06 F0 55 AA 52 08 07
				39 00 00 00 00 00 02 D9 40
				39 00 00 00 00 00 02 6F 01
				39 00 00 00 00 00 05 88 02 1C 08 65
				39 00 00 00 00 00 03 87 1F FF
				39 00 00 00 00 00 03 51 07 FF
				39 00 00 00 00 00 02 88 01
				39 01 00 00 21 00 02 85 01
			];
			mi,mdss-dsi-local-hbm-hlpm-white-1000nit-command-state = "dsi_hs_mode";

			mi,mdss-dsi-local-hbm-normal-white-110nit-command = [
				39 01 00 00 00 00 06 F0 55 AA 52 08 00
				39 00 00 00 00 00 02 6F 17
				39 00 00 00 00 00 03 B2 07 FF
				39 00 00 00 00 00 02 6F 1F
				39 00 00 00 00 00 03 B2 00 50
				39 00 00 00 00 00 06 F0 55 AA 52 08 02
				39 00 00 00 00 00 02 D1 01
				39 00 00 00 00 00 02 6F 08
				39 00 00 00 00 00 07 D0 07 62 06 74 07 F7
				39 00 00 00 00 00 06 F0 55 AA 52 08 07
				39 00 00 00 00 00 02 D9 40
				39 00 00 00 00 00 02 6F 01
				39 00 00 00 00 00 05 88 02 1C 08 65
				39 00 00 00 00 00 03 87 1F FF
				39 00 00 00 00 00 03 51 07 FF
				39 00 00 00 00 00 02 88 01
				39 01 00 00 21 00 02 85 01
			];
			mi,mdss-dsi-local-hbm-normal-white-110nit-command-state = "dsi_hs_mode";

			mi,mdss-dsi-local-hbm-hlpm-white-110nit-command = [
				/* AOD off */
				39 01 00 00 32 00 02 38 00
				39 00 00 00 00 00 02 2C 00
				/* 120HZ */
				39 00 00 00 00 00 02 2F 03
				/* Local HBM setting*/
				39 00 00 00 00 00 06 F0 55 AA 52 08 00
				39 00 00 00 00 00 02 6F 17
				39 00 00 00 00 00 03 B2 07 FF
				39 00 00 00 00 00 02 6F 1F
				39 00 00 00 00 00 03 B2 00 50
				39 00 00 00 00 00 06 F0 55 AA 52 08 02
				39 00 00 00 00 00 02 D1 01
				39 00 00 00 00 00 02 6F 08
				39 00 00 00 00 00 07 D0 07 62 06 74 07 F7
				39 00 00 00 00 00 06 F0 55 AA 52 08 07
				39 00 00 00 00 00 02 D9 40
				39 00 00 00 00 00 02 6F 01
				39 00 00 00 00 00 05 88 02 1C 08 65
				39 00 00 00 00 00 03 87 1F FF
				39 00 00 00 00 00 03 51 07 FF
				39 00 00 00 00 00 02 88 01
				39 01 00 00 21 00 02 85 01
			];
			mi,mdss-dsi-local-hbm-hlpm-white-110nit-command-state = "dsi_hs_mode";

			mi,mdss-dsi-local-hbm-normal-green-500nit-command = [
				39 01 00 00 00 00 06 F0 55 AA 52 08 00
				39 00 00 00 00 00 02 6F 17
				39 00 00 00 00 00 03 B2 07 FF
				39 00 00 00 00 00 02 6F 1F
				39 00 00 00 00 00 03 B2 00 50
				39 00 00 00 00 00 06 F0 55 AA 52 08 02
				39 00 00 00 00 00 02 D1 01
				39 00 00 00 00 00 02 6F 08
				39 00 00 00 00 00 07 D0 00 00 09 40 00 00
				39 00 00 00 00 00 06 F0 55 AA 52 08 07
				39 00 00 00 00 00 02 D9 40
				39 00 00 00 00 00 02 6F 01
				39 00 00 00 00 00 05 88 02 1C 08 65
				39 00 00 00 00 00 03 87 1F FF
				39 00 00 00 00 00 03 51 07 FF
				39 00 00 00 00 00 02 88 01
				39 01 00 00 21 00 02 85 01
			];
			mi,mdss-dsi-local-hbm-normal-green-500nit-command-state = "dsi_hs_mode";

			mi,mdss-dsi-local-hbm-off-to-normal-command = [
				39 01 00 00 00 00 02 53 20
				39 00 00 00 00 00 03 51 00 00
				39 00 00 00 00 00 03 87 0F FF
				39 00 00 00 00 00 02 88 01
				39 01 00 00 0A 00 02 86 01
			];
			mi,mdss-dsi-local-hbm-off-to-normal-command-state = "dsi_hs_mode";

			mi,mdss-dsi-local-hbm-off-to-hbm-command = [
				39 01 00 00 00 00 02 53 20
				39 00 00 00 00 00 03 51 00 00
				39 00 00 00 00 00 03 87 0F FF
				39 00 00 00 00 00 02 88 01
				39 01 00 00 0A 00 02 86 01
			];
			mi,mdss-dsi-local-hbm-off-to-hbm-command-state = "dsi_hs_mode";

			mi,mdss-dsi-local-hbm-off-to-hlpm-command = [
				/* local hbm off */
				39 01 00 00 00 00 02 53 20
				39 00 00 00 00 00 03 51 00 00
				39 00 00 00 00 00 03 87 0F FF
				39 00 00 00 00 00 02 88 01
				39 01 00 00 0A 00 02 86 01
				/* aod hbm */
				39 01 00 00 14 00 02 39 00
				39 01 00 00 00 00 02 2C 00
			];
			mi,mdss-dsi-local-hbm-off-to-hlpm-command-state = "dsi_hs_mode";

			mi,mdss-dsi-local-hbm-off-to-llpm-command = [
				/* local hbm off */
				39 01 00 00 00 00 02 53 20
				39 00 00 00 00 00 03 51 00 00
				39 00 00 00 00 00 03 87 0F FF
				39 00 00 00 00 00 02 88 01
				39 01 00 00 0A 00 02 86 01
				/* aod lbm */
				39 01 00 00 14 00 02 39 00
				39 01 00 00 00 00 02 2C 00
			];
			mi,mdss-dsi-local-hbm-off-to-llpm-command-state = "dsi_hs_mode";

			mi,mdss-dsi-flat-mode-on-command = [
				/* page 0 */
				39 01 00 00 00 00 06 F0 55 AA 52 08 00
				/* 120Hz */
				39 00 00 00 09 00 02 2F 03
				/* GIR ON */
				39 00 00 00 00 00 02 5F 00
				39 00 00 00 00 00 06 F0 55 AA 52 08 00
				39 00 00 00 00 00 02 6F 0A
				/* Preset3 gamma */
				39 00 00 00 00 00 02 C0 60
				/* page 2 */
				39 00 00 00 00 00 06 F0 55 AA 52 08 02
				39 00 00 00 00 00 02 CC 30
				39 01 00 00 14 00 02 CE 01
				39 01 00 00 00 00 02 CC 00
			];
			mi,mdss-dsi-flat-mode-on-command-state = "dsi_hs_mode";

			mi,mdss-dsi-flat-mode-off-command = [
				/* Page 0 */
				39 01 00 00 00 00 06 F0 55 AA 52 08 00
				/* 120Hz */
				39 00 00 00 00 00 02 2F 03
				/* GIR OFF */
				39 00 00 00 00 00 02 5F 01
				39 00 00 00 00 00 06 F0 55 AA 52 08 00
				39 00 00 00 00 00 02 6F 0A
				/* Preset1 gamma */
				39 00 00 00 00 00 02 C0 20
				/* Page 2 */
				39 00 00 00 00 00 06 F0 55 AA 52 08 02
				39 00 00 00 00 00 02 CC 30
				39 01 00 00 14 00 02 CE 01
				39 01 00 00 00 00 02 CC 00
			];
			mi,mdss-dsi-flat-mode-off-command-state = "dsi_hs_mode";

			mi,mdss-dsi-timing-switch-gir-command = [
				/* Frame Rate 120Hz GIR ON */
				/* page 0 */
				39 01 00 00 00 00 06 F0 55 AA 52 08 00
				/* 120Hz */
				39 00 00 00 09 00 02 2F 03
				/* GIR ON */
				39 00 00 00 00 00 02 5F 00
				39 00 00 00 00 00 06 F0 55 AA 52 08 00
				39 00 00 00 00 00 02 6F 0A
				/* Preset3 gamma */
				39 00 00 00 00 00 02 C0 60
				/* page 2 */
				39 00 00 00 00 00 06 F0 55 AA 52 08 02
				39 00 00 00 00 00 02 CC 30
				39 01 00 00 14 00 02 CE 01
				39 01 00 00 00 00 02 CC 00
			];
			mi,mdss-dsi-timing-switch-gir-command-state = "dsi_hs_mode";

			mi,mdss-dsi-pre-doze-to-off-command = [
				39 01 00 00 00 00 06 F0 55 AA 52 08 01
				39 01 00 00 00 00 02 CE 0C];
			mi,mdss-dsi-pre-doze-to-off-command-state = "dsi_hs_mode";
		};
	};
};
